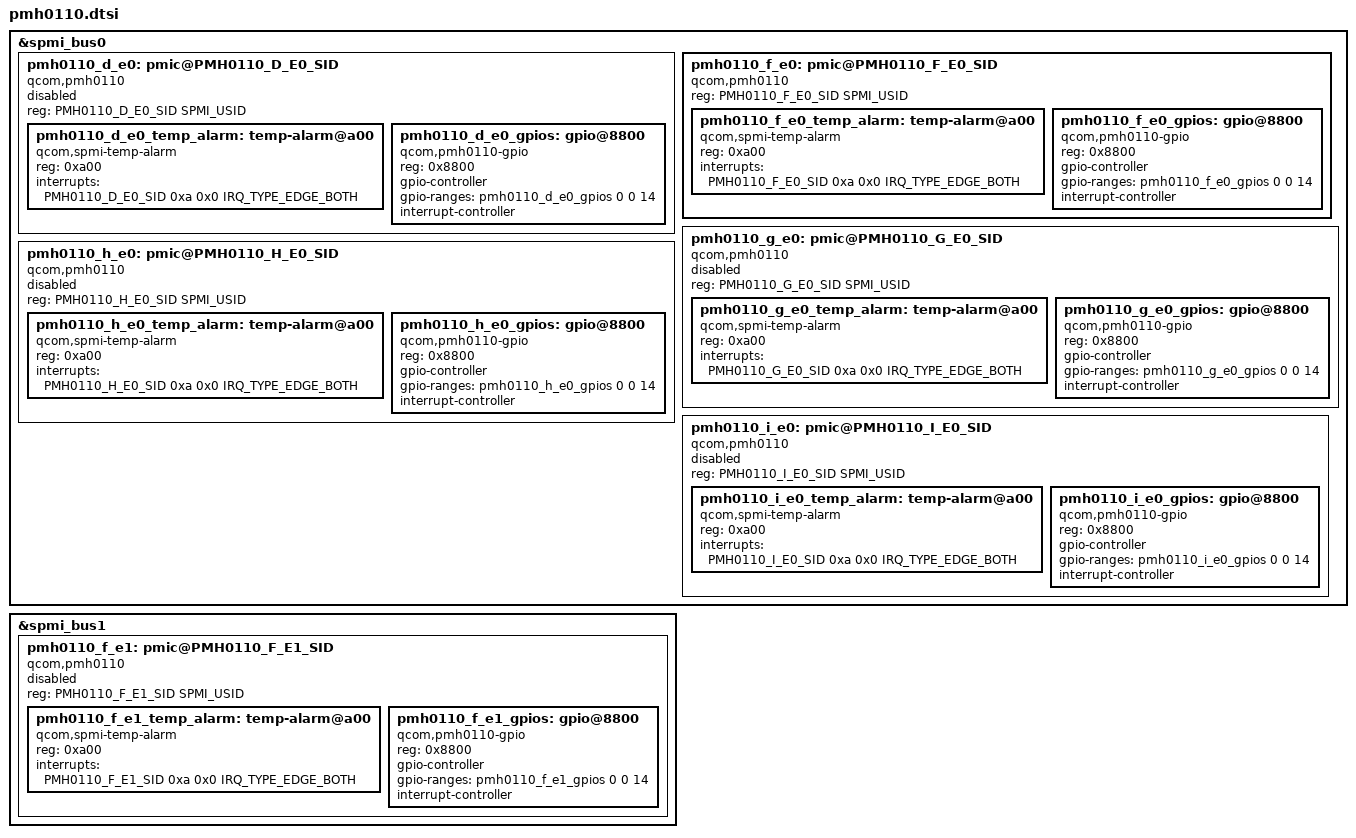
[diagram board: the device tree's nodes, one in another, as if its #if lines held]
// SPDX-License-Identifier: BSD-3-Clause-Clear
/*
 * Copyright (c) Qualcomm Technologies, Inc. and/or its subsidiaries.
 */

#include <dt-bindings/interrupt-controller/irq.h>
#include <dt-bindings/spmi/spmi.h>

&spmi_bus0 {

#ifdef PMH0110_D_E0_SID
	pmh0110_d_e0: pmic@PMH0110_D_E0_SID {
		compatible = "qcom,pmh0110", "qcom,spmi-pmic";
		reg = <PMH0110_D_E0_SID SPMI_USID>;
		#address-cells = <1>;
		#size-cells = <0>;
		status = "disabled";

		pmh0110_d_e0_temp_alarm: temp-alarm@a00 {
			compatible = "qcom,spmi-temp-alarm";
			reg = <0xa00>;
			interrupts = <PMH0110_D_E0_SID 0xa 0x0 IRQ_TYPE_EDGE_BOTH>;
			#thermal-sensor-cells = <0>;
		};

		pmh0110_d_e0_gpios: gpio@8800 {
			compatible = "qcom,pmh0110-gpio", "qcom,spmi-gpio";
			reg = <0x8800>;
			gpio-controller;
			gpio-ranges = <&pmh0110_d_e0_gpios 0 0 14>;
			#gpio-cells = <2>;
			interrupt-controller;
			#interrupt-cells = <2>;
		};
	};
#endif

#ifdef PMH0110_F_E0_SID
	pmh0110_f_e0: pmic@PMH0110_F_E0_SID {
		compatible = "qcom,pmh0110", "qcom,spmi-pmic";
		reg = <PMH0110_F_E0_SID SPMI_USID>;
		#address-cells = <1>;
		#size-cells = <0>;

		pmh0110_f_e0_temp_alarm: temp-alarm@a00 {
			compatible = "qcom,spmi-temp-alarm";
			reg = <0xa00>;
			interrupts = <PMH0110_F_E0_SID 0xa 0x0 IRQ_TYPE_EDGE_BOTH>;
			#thermal-sensor-cells = <0>;
		};

		pmh0110_f_e0_gpios: gpio@8800 {
			compatible = "qcom,pmh0110-gpio", "qcom,spmi-gpio";
			reg = <0x8800>;
			gpio-controller;
			gpio-ranges = <&pmh0110_f_e0_gpios 0 0 14>;
			#gpio-cells = <2>;
			interrupt-controller;
			#interrupt-cells = <2>;
		};
	};
#endif

#ifdef PMH0110_G_E0_SID
	pmh0110_g_e0: pmic@PMH0110_G_E0_SID {
		compatible = "qcom,pmh0110", "qcom,spmi-pmic";
		reg = <PMH0110_G_E0_SID SPMI_USID>;
		#address-cells = <1>;
		#size-cells = <0>;
		status = "disabled";

		pmh0110_g_e0_temp_alarm: temp-alarm@a00 {
			compatible = "qcom,spmi-temp-alarm";
			reg = <0xa00>;
			interrupts = <PMH0110_G_E0_SID 0xa 0x0 IRQ_TYPE_EDGE_BOTH>;
			#thermal-sensor-cells = <0>;
		};

		pmh0110_g_e0_gpios: gpio@8800 {
			compatible = "qcom,pmh0110-gpio", "qcom,spmi-gpio";
			reg = <0x8800>;
			gpio-controller;
			gpio-ranges = <&pmh0110_g_e0_gpios 0 0 14>;
			#gpio-cells = <2>;
			interrupt-controller;
			#interrupt-cells = <2>;
		};
	};
#endif

#ifdef PMH0110_H_E0_SID
	pmh0110_h_e0: pmic@PMH0110_H_E0_SID {
		compatible = "qcom,pmh0110", "qcom,spmi-pmic";
		reg = <PMH0110_H_E0_SID SPMI_USID>;
		#address-cells = <1>;
		#size-cells = <0>;
		status = "disabled";

		pmh0110_h_e0_temp_alarm: temp-alarm@a00 {
			compatible = "qcom,spmi-temp-alarm";
			reg = <0xa00>;
			interrupts = <PMH0110_H_E0_SID 0xa 0x0 IRQ_TYPE_EDGE_BOTH>;
			#thermal-sensor-cells = <0>;
		};

		pmh0110_h_e0_gpios: gpio@8800 {
			compatible = "qcom,pmh0110-gpio", "qcom,spmi-gpio";
			reg = <0x8800>;
			gpio-controller;
			gpio-ranges = <&pmh0110_h_e0_gpios 0 0 14>;
			#gpio-cells = <2>;
			interrupt-controller;
			#interrupt-cells = <2>;
		};
	};
#endif

#ifdef PMH0110_I_E0_SID
	pmh0110_i_e0: pmic@PMH0110_I_E0_SID {
		compatible = "qcom,pmh0110", "qcom,spmi-pmic";
		reg = <PMH0110_I_E0_SID SPMI_USID>;
		#address-cells = <1>;
		#size-cells = <0>;
		status = "disabled";

		pmh0110_i_e0_temp_alarm: temp-alarm@a00 {
			compatible = "qcom,spmi-temp-alarm";
			reg = <0xa00>;
			interrupts = <PMH0110_I_E0_SID 0xa 0x0 IRQ_TYPE_EDGE_BOTH>;
			#thermal-sensor-cells = <0>;
		};

		pmh0110_i_e0_gpios: gpio@8800 {
			compatible = "qcom,pmh0110-gpio", "qcom,spmi-gpio";
			reg = <0x8800>;
			gpio-controller;
			gpio-ranges = <&pmh0110_i_e0_gpios 0 0 14>;
			#gpio-cells = <2>;
			interrupt-controller;
			#interrupt-cells = <2>;
		};
	};
#endif
};

&spmi_bus1 {
#ifdef PMH0110_F_E1_SID
	pmh0110_f_e1: pmic@PMH0110_F_E1_SID {
		compatible = "qcom,pmh0110", "qcom,spmi-pmic";
		reg = <PMH0110_F_E1_SID SPMI_USID>;
		#address-cells = <1>;
		#size-cells = <0>;
		status = "disabled";

		pmh0110_f_e1_temp_alarm: temp-alarm@a00 {
			compatible = "qcom,spmi-temp-alarm";
			reg = <0xa00>;
			interrupts = <PMH0110_F_E1_SID 0xa 0x0 IRQ_TYPE_EDGE_BOTH>;
			#thermal-sensor-cells = <0>;
		};

		pmh0110_f_e1_gpios: gpio@8800 {
			compatible = "qcom,pmh0110-gpio", "qcom,spmi-gpio";
			reg = <0x8800>;
			gpio-controller;
			gpio-ranges = <&pmh0110_f_e1_gpios 0 0 14>;
			#gpio-cells = <2>;
			interrupt-controller;
			#interrupt-cells = <2>;
		};
	};
#endif
};
